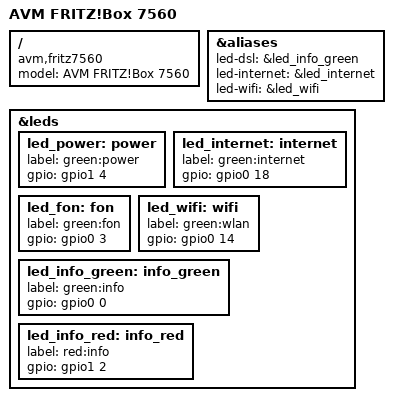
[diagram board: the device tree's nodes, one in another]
// SPDX-License-Identifier: GPL-2.0-or-later OR MIT

#include "xrx500.dtsi"

/dts-v1/;
/ {
	compatible = "avm,fritz7560", "intel,easy350-anywan", "intel,xrx500";
	model = "AVM FRITZ!Box 7560";
};

&aliases {
	led-dsl = &led_info_green;
	led-internet = &led_internet;
	led-wifi = &led_wifi;
};

&leds {
	led_power: power {
		label = "green:power";
		gpio = <&gpio1 4 GPIO_ACTIVE_HIGH>;
	};
	led_internet: internet {
		label = "green:internet";
		gpio = <&gpio0 18 GPIO_ACTIVE_HIGH>;
	};
	led_fon: fon {
		label = "green:fon";
		gpio = <&gpio0 3 GPIO_ACTIVE_HIGH>;
	};
	led_wifi: wifi {
		label = "green:wlan";
		gpio = <&gpio0 14 GPIO_ACTIVE_HIGH>;
	};
	led_info_green: info_green {
		label = "green:info";
		gpio = <&gpio0 0 GPIO_ACTIVE_HIGH>;
	};
	led_info_red: info_red {
		label = "red:info";
		gpio = <&gpio1 2 GPIO_ACTIVE_HIGH>;
	};
};
